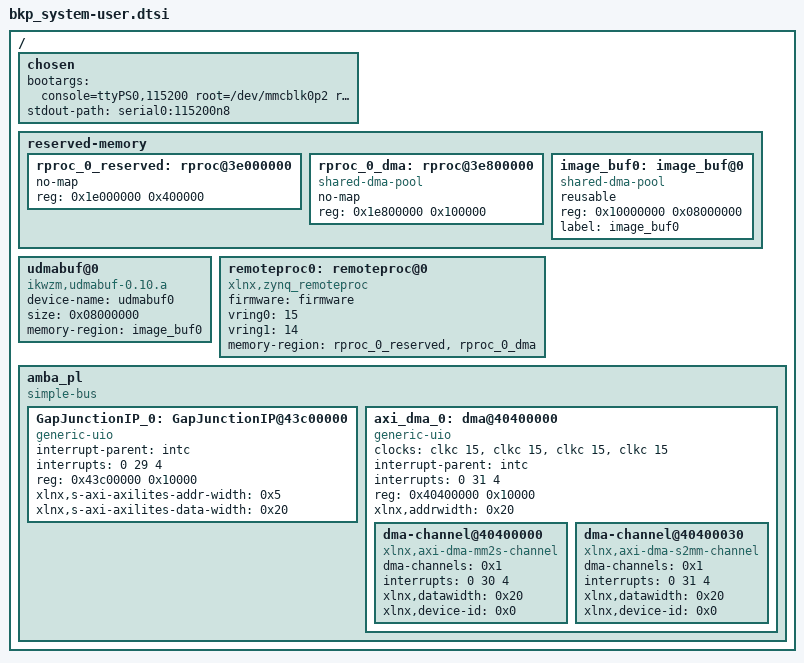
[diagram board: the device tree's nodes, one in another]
/include/ "system-conf.dtsi"
/include/ "pl.dtsi"

/ {
	chosen {
		bootargs = "console=ttyPS0,115200 root=/dev/mmcblk0p2 rw earlyprintk rootfstype=ext4 rootwait devtmpfs.mount=0 uio_pdrv_genirq.of_id=generic-uio";
		stdout-path = "serial0:115200n8";
	};

	reserved-memory {
		#address-cells = <1>;
		#size-cells = <1>;
		ranges;

		rproc_0_reserved: rproc@3e000000 {
			no-map;
			reg = <0x1e000000 0x400000>;
		};
		rproc_0_dma: rproc@3e800000 {
			no-map;
			compatible = "shared-dma-pool";
			reg = <0x1e800000 0x100000>;
		};

		image_buf0: image_buf@0 {
			compatible = "shared-dma-pool";
			reusable;
			reg = <0x10000000 0x08000000>; 
			label = "image_buf0";
		};

	};

	udmabuf@0 {
		compatible = "ikwzm,udmabuf-0.10.a";
		device-name = "udmabuf0";
		size = <0x08000000>; // 128MiB
		memory-region = <&image_buf0>;
	};

	remoteproc0: remoteproc@0 {
		compatible = "xlnx,zynq_remoteproc";
		firmware = "firmware";
		vring0 = <15>;
		vring1 = <14>;
		memory-region = <&rproc_0_reserved>, <&rproc_0_dma>;
	};

	amba_pl:amba_pl {
    		#address-cells = <1>;
    		#size-cells = <1>;
    		compatible = "simple-bus";
    		ranges ;
    
		GapJunctionIP_0: GapJunctionIP@43c00000 {
        		compatible = "generic-uio";
        		interrupt-parent = <&intc>;
        		interrupts = <0 29 4>;
        		reg = <0x43c00000 0x10000>;
        		xlnx,s-axi-axilites-addr-width = <0x5>;
        		xlnx,s-axi-axilites-data-width = <0x20>;
    		};
    
		axi_dma_0: dma@40400000 {
        		#dma-cells = <1>;
        		clock-names = "s_axi_lite_aclk", "m_axi_sg_aclk", "m_axi_mm2s_aclk", "m_axi_s2mm_aclk";
        		clocks = <&clkc 15>, <&clkc 15>, <&clkc 15>, <&clkc 15>;
        		compatible = "generic-uio";
        		interrupt-parent = <&intc>;
        		interrupts = <0 31 4>;
        		reg = <0x40400000 0x10000>;
        		xlnx,addrwidth = <0x20>;
        		dma-channel@40400000 {
            			compatible = "xlnx,axi-dma-mm2s-channel";
            			dma-channels = <0x1>;
            			interrupts = <0 30 4>;
            			xlnx,datawidth = <0x20>;
            			xlnx,device-id = <0x0>;
       		 	};
        		dma-channel@40400030 {
            			compatible = "xlnx,axi-dma-s2mm-channel";
            			dma-channels = <0x1>;
            			interrupts = <0 31 4>;
            			xlnx,datawidth = <0x20>;
            			xlnx,device-id = <0x0>;
        		};
    		};
	};
};
